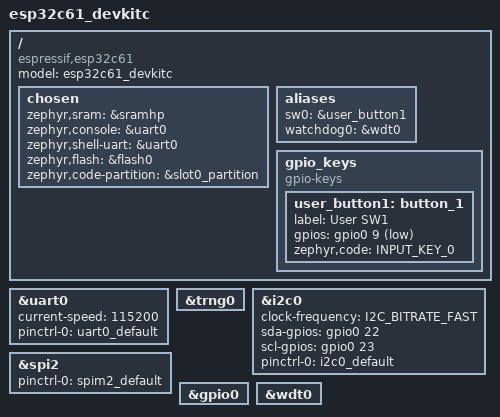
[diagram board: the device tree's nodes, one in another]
/*
 * Copyright (c) 2026 Espressif Systems (Shanghai) Co., Ltd.
 *
 * SPDX-License-Identifier: Apache-2.0
 */

/dts-v1/;

#include <espressif/esp32c61/esp32c61_wroom_n8r2.dtsi>
#include "esp32c61_devkitc-pinctrl.dtsi"
#include <zephyr/dt-bindings/input/input-event-codes.h>
#include <espressif/partitions_0x0_default.dtsi>

/ {
	model = "esp32c61_devkitc";
	compatible = "espressif,esp32c61";

	chosen {
		zephyr,sram = &sramhp;
		zephyr,console = &uart0;
		zephyr,shell-uart = &uart0;
		zephyr,flash = &flash0;
		zephyr,code-partition = &slot0_partition;
	};

	aliases {
		sw0 = &user_button1;
		watchdog0 = &wdt0;
	};

	gpio_keys {
		compatible = "gpio-keys";

		user_button1: button_1 {
			label = "User SW1";
			gpios = <&gpio0 9 (GPIO_PULL_UP | GPIO_ACTIVE_LOW)>;
			zephyr,code = <INPUT_KEY_0>;
		};
	};
};

&uart0 {
	status = "okay";
	current-speed = <115200>;
	pinctrl-0 = <&uart0_default>;
	pinctrl-names = "default";
};

&trng0 {
	status = "okay";
};

&i2c0 {
	status = "okay";
	clock-frequency = <I2C_BITRATE_FAST>;
	sda-gpios = <&gpio0 22 GPIO_OPEN_DRAIN>;
	scl-gpios = <&gpio0 23 GPIO_OPEN_DRAIN>;
	pinctrl-0 = <&i2c0_default>;
	pinctrl-names = "default";
};

&spi2 {
	#address-cells = <1>;
	#size-cells = <0>;
	status = "okay";
	pinctrl-0 = <&spim2_default>;
	pinctrl-names = "default";
};

&gpio0 {
	status = "okay";
};

&wdt0 {
	status = "okay";
};
